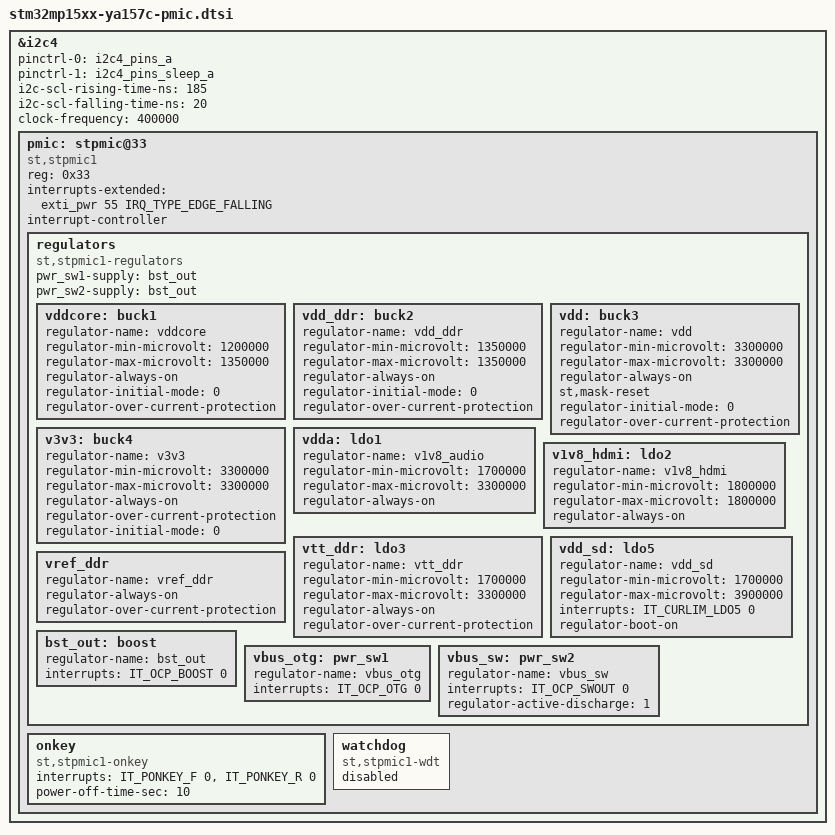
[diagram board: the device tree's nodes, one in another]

#include <dt-bindings/mfd/st,stpmic1.h>

&i2c4 {
	pinctrl-names = "default", "sleep";
	pinctrl-0 = <&i2c4_pins_a>;
	pinctrl-1 = <&i2c4_pins_sleep_a>;
	i2c-scl-rising-time-ns = <185>;
	i2c-scl-falling-time-ns = <20>;
	clock-frequency = <400000>;
	status = "okay";
	/* spare dmas for other usage */
	/delete-property/dmas;
	/delete-property/dma-names;

	pmic: stpmic@33 {
		compatible = "st,stpmic1";
		reg = <0x33>;
		interrupts-extended = <&exti_pwr 55 IRQ_TYPE_EDGE_FALLING>;
		interrupt-controller;
		#interrupt-cells = <2>;
		status = "okay";

		regulators {
			compatible = "st,stpmic1-regulators";
		
			pwr_sw1-supply = <&bst_out>;
			pwr_sw2-supply = <&bst_out>;

			vddcore: buck1 {
				regulator-name = "vddcore";
				regulator-min-microvolt = <1200000>;
				regulator-max-microvolt = <1350000>;
				regulator-always-on;
				regulator-initial-mode = <0>;
				regulator-over-current-protection;
			};

			vdd_ddr: buck2 {
				regulator-name = "vdd_ddr";
				regulator-min-microvolt = <1350000>;
				regulator-max-microvolt = <1350000>;
				regulator-always-on;
				regulator-initial-mode = <0>;
				regulator-over-current-protection;
			};

			vdd: buck3 {
				regulator-name = "vdd";
				regulator-min-microvolt = <3300000>;
				regulator-max-microvolt = <3300000>;
				regulator-always-on;
				st,mask-reset;
				regulator-initial-mode = <0>;
				regulator-over-current-protection;
			};

			v3v3: buck4 {
				regulator-name = "v3v3";
				regulator-min-microvolt = <3300000>;
				regulator-max-microvolt = <3300000>;
				regulator-always-on;
				regulator-over-current-protection;
				regulator-initial-mode = <0>;
			};
			
			/*none*/
			vdda: ldo1 {
				regulator-name = "v1v8_audio";
				regulator-min-microvolt = <1700000>;
				regulator-max-microvolt = <3300000>;
				regulator-always-on;
				//interrupts = <IT_CURLIM_LDO1 0>;

			};

			v1v8_hdmi: ldo2 {
				regulator-name = "v1v8_hdmi";
				regulator-min-microvolt = <1800000>;
				regulator-max-microvolt = <1800000>;
				regulator-always-on;
				//interrupts = <IT_CURLIM_LDO2 0>;

			};

			vtt_ddr: ldo3 {
				regulator-name = "vtt_ddr";
				regulator-min-microvolt = <1700000>;
				regulator-max-microvolt = <3300000>;
				regulator-always-on;
				regulator-over-current-protection;
			};
/*
			vdd_usb: ldo4 {
				regulator-name = "vdd_usb";
				regulator-min-microvolt = <3300000>;
				regulator-max-microvolt = <3300000>;
				interrupts = <IT_CURLIM_LDO4 0>;
				regulator-always-on;
			};
*/

			vdd_sd: ldo5 {
				regulator-name = "vdd_sd";
				regulator-min-microvolt = <1700000>;
				regulator-max-microvolt = <3900000>;
				interrupts = <IT_CURLIM_LDO5 0>;
				regulator-boot-on;
			};

			vref_ddr: vref_ddr {
				regulator-name = "vref_ddr";
				regulator-always-on;
				regulator-over-current-protection;
			};

			 bst_out: boost {
				regulator-name = "bst_out";
				interrupts = <IT_OCP_BOOST 0>;
			 };

			vbus_otg: pwr_sw1 {
				regulator-name = "vbus_otg";
				interrupts = <IT_OCP_OTG 0>;
			 };

			 vbus_sw: pwr_sw2 {
				regulator-name = "vbus_sw";
				interrupts = <IT_OCP_SWOUT 0>;
				regulator-active-discharge = <1>;
			 };
		};

		onkey {
			compatible = "st,stpmic1-onkey";
			interrupts = <IT_PONKEY_F 0>, <IT_PONKEY_R 0>;
			interrupt-names = "onkey-falling", "onkey-rising";
			power-off-time-sec = <10>;
			status = "okay";
		};

		watchdog {
			compatible = "st,stpmic1-wdt";
			status = "disabled";
		};
    };
};


